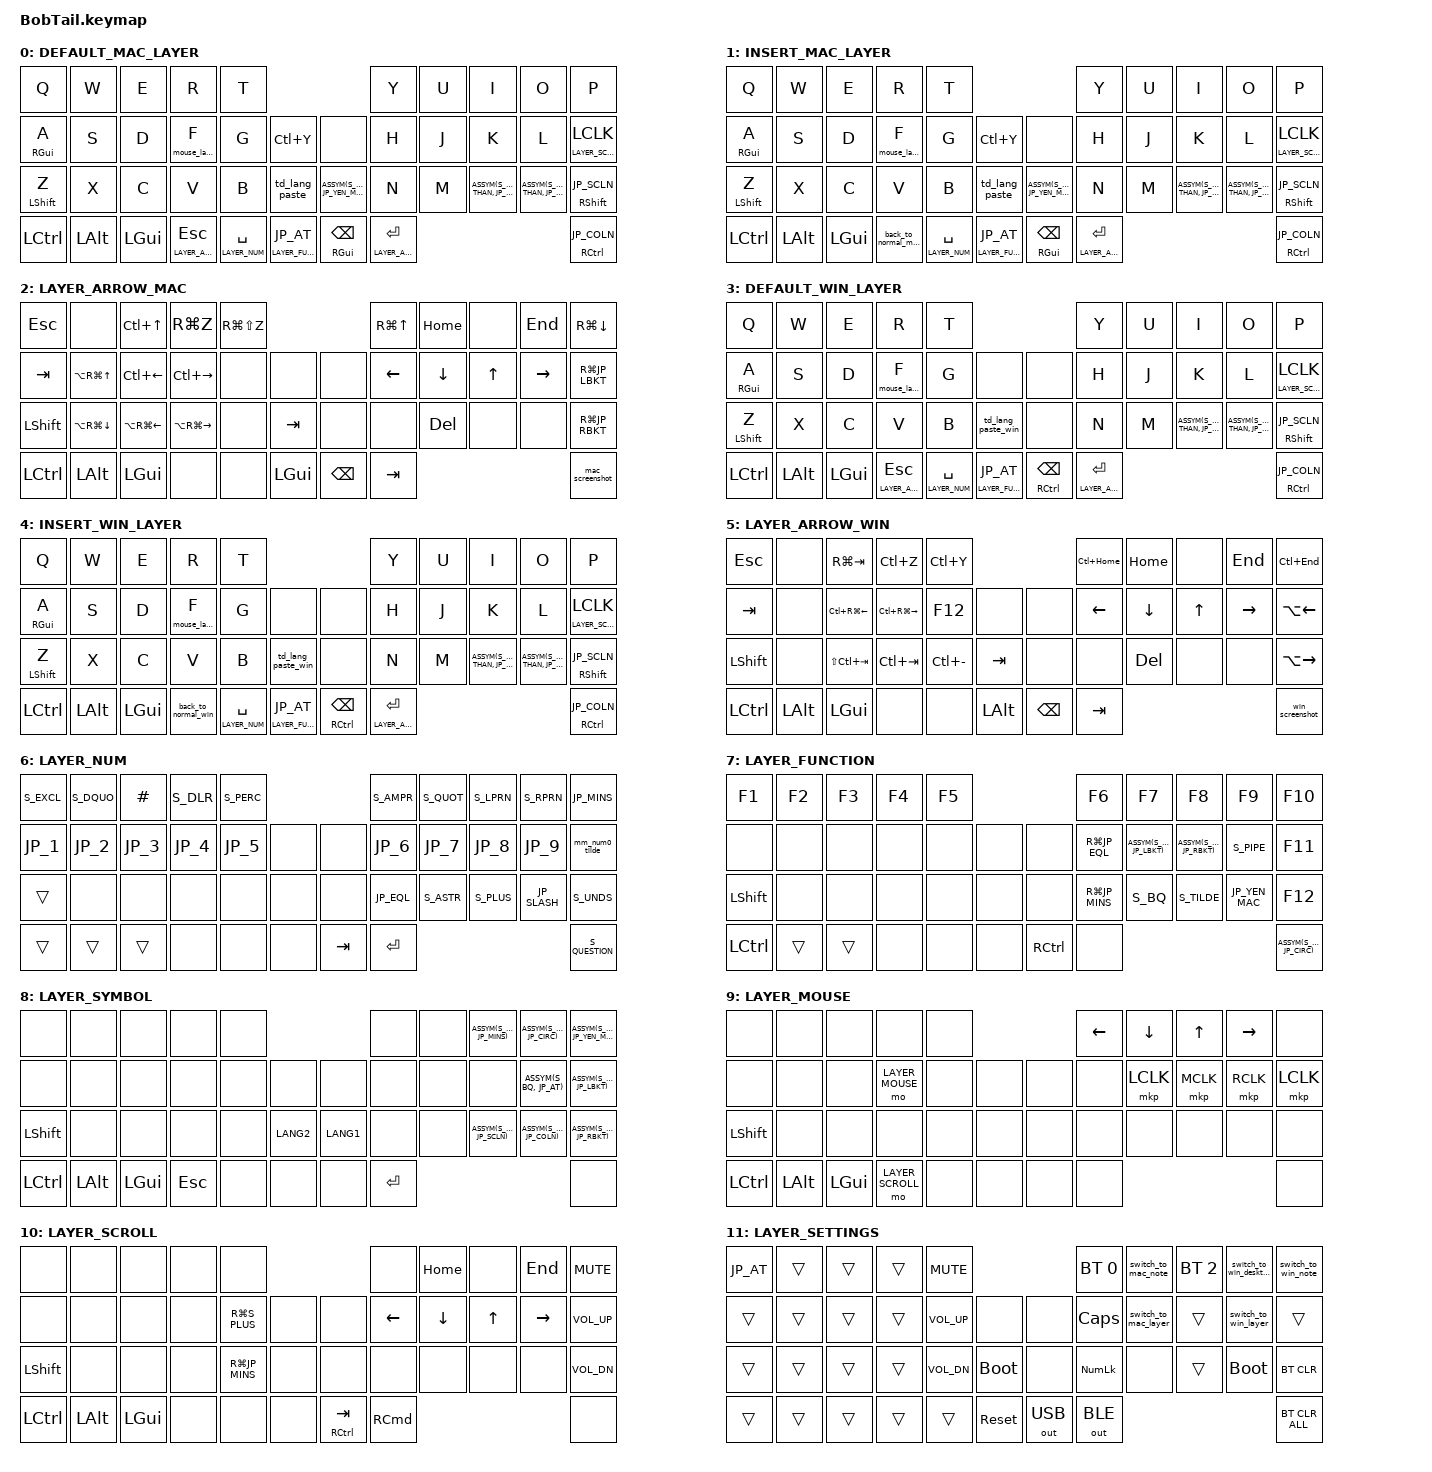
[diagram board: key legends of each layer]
#include <behaviors.dtsi>
#include <dt-bindings/zmk/bt.h>
#include <dt-bindings/zmk/keys.h>
#include <dt-bindings/zmk/outputs.h>
#define ZMK_POINTING_DEFAULT_SCRL_VAL 80
#include <dt-bindings/zmk/pointing.h>
#include <input/processors.dtsi>

#define ASSYM(shifted, keycode) &auto_shift shifted keycode
#include "code.h"

//レイヤー情報
#define DEFAULT_MAC_LAYER 0
#define INSERT_MAC_LAYER 1
#define LAYER_ARROW_MAC 2
#define DEFAULT_WIN_LAYER 3
#define INSERT_WIN_LAYER 4
#define LAYER_ARROW_WIN 5
#define LAYER_NUM 6
#define LAYER_FUNCTION 7
#define LAYER_SYMBOL 8
#define LAYER_MOUSE 9
#define LAYER_SCROLL 10
#define LAYER_SETTINGS 11


&mt {
    flavor = "balanced";
    quick-tap-ms = <0>;
};

/ {
    combos {
        compatible = "zmk,combos";
        to_layer_symbol {
            timeout-ms = <50>;
            bindings = <&toggle_symbol>;
            key-positions = <11 12>;
            layers = <DEFAULT_MAC_LAYER DEFAULT_WIN_LAYER LAYER_SYMBOL>;
        };
        to_layer_settings {
            bindings = <&mo LAYER_SETTINGS>;
            key-positions = <37 38>;
        };
        back_to_default_mac_combo {
            timeout-ms = <800>;
            key-positions = <37 41>;
            bindings = <&back_to_default_mac>;
            layers = <INSERT_MAC_LAYER DEFAULT_MAC_LAYER>;
        };
        back_to_default_win_combo {
            timeout-ms = <800>;
            key-positions = <37 41>;
            bindings = <&back_to_default_win>;
            layers = <INSERT_WIN_LAYER DEFAULT_WIN_LAYER>;
        };
        combo_pipe {
            timeout-ms = <300>;
            key-positions = <13 9>;
            bindings = <&macro_pipe>;
        };
        combo_yen {
            timeout-ms = <300>;
            key-positions = <13 21>;
            bindings = <&macro_yen>;
        };
        combo_under {
            timeout-ms = <300>;
            key-positions = <13 33>;
            bindings = <&macro_under>;
        };
        combo_middle_click {
            timeout-ms = <40>;
            key-positions = <19 20>;
            bindings = <&mkp MCLK>;
            slow-release;
        };
        combo_right_click {
            timeout-ms = <40>;
            key-positions = <20 21>;
            bindings = <&mkp RCLK>;
            slow-release;
        };
    };

    macros {
        mouse_layer_eisu_hold: mouse_layer_eisu_hold {
            compatible = "zmk,behavior-macro";
            #binding-cells = <0>;
            wait-ms = <0>;
            tap-ms = <40>;
            bindings = <&macro_press &mo LAYER_MOUSE>, <&macro_pause_for_release>, <&macro_release &mo LAYER_MOUSE>;
        };
        mouse_button_eisu: mouse_button_eisu {
            compatible = "zmk,behavior-macro-one-param";
            #binding-cells = <1>;
            wait-ms = <30>;
            tap-ms = <40>;
            bindings = <&macro_param_1to1>, <&macro_tap &mkp MACRO_PLACEHOLDER>;
        };
        macro_pipe: macro_pipe {
            compatible = "zmk,behavior-macro";
            #binding-cells = <0>;
            bindings = <&macro_press &kp LALT>, <&macro_tap &kp KP_N1 &kp KP_N2 &kp KP_N4>, <&macro_release &kp LALT>;
        };
        macro_yen: macro_yen {
            compatible = "zmk,behavior-macro";
            #binding-cells = <0>;
            bindings = <&macro_press &kp LALT>, <&macro_tap &kp KP_N1 &kp KP_N6 &kp KP_N5>, <&macro_release &kp LALT>;
        };
        macro_under: macro_under {
            compatible = "zmk,behavior-macro";
            #binding-cells = <0>;
            bindings = <&macro_press &kp LALT>, <&macro_tap &kp KP_N9 &kp KP_N5>, <&macro_release &kp LALT>;
        };
        switch_to_mac_note: switch_to_mac_note {
            compatible = "zmk,behavior-macro";
            #binding-cells = <0>;
            bindings = <&macro_wait_time 50 &bt BT_SEL 1 &bt BT_DISC 0 &bt BT_DISC 2 &bt BT_DISC 3 &bt BT_DISC 4 &out OUT_BLE>;
        };
        switch_to_win_desktop: switch_to_win_desktop {
            compatible = "zmk,behavior-macro";
            #binding-cells = <0>;
            bindings = <&macro_wait_time 50 &bt BT_SEL 3 &bt BT_DISC 0 &bt BT_DISC 1 &bt BT_DISC 2 &bt BT_DISC 4 &out OUT_BLE>;
        };
        switch_to_win_note: switch_to_win_note {
            compatible = "zmk,behavior-macro";
            #binding-cells = <0>;
            bindings = <&macro_wait_time 50 &bt BT_SEL 4 &bt BT_DISC 0 &bt BT_DISC 1 &bt BT_DISC 2 &bt BT_DISC 3 &out OUT_BLE>;
        };
        reset_default_layer: reset_default_layer {
            compatible = "zmk,behavior-macro";
            #binding-cells = <0>;
            bindings = <&toggle_off DEFAULT_MAC_LAYER &toggle_off DEFAULT_WIN_LAYER>;
        };
        switch_to_mac_layer: switch_to_mac_layer {
            compatible = "zmk,behavior-macro";
            #binding-cells = <0>;
            bindings = <&reset_default_layer &macro_wait_time 200 &bt BT_DISC 3 &bt BT_DISC 4 &toggle_on DEFAULT_MAC_LAYER &to DEFAULT_MAC_LAYER &out OUT_BLE>;
        };
        switch_to_win_layer: switch_to_win_layer {
            compatible = "zmk,behavior-macro";
            #binding-cells = <0>;
            bindings = <&reset_default_layer &macro_wait_time 200 &bt BT_DISC 0 &bt BT_DISC 1 &bt BT_DISC 2 &toggle_on DEFAULT_WIN_LAYER &to DEFAULT_WIN_LAYER &out OUT_BLE>;
        };
        mac_screenshot: mac_screenshot {
            compatible = "zmk,behavior-macro";
            #binding-cells = <0>;
            bindings = <&kp RG(LS(N5))>;
        };
        win_screenshot: win_screenshot {
            compatible = "zmk,behavior-macro";
            #binding-cells = <0>;
            bindings = <&kp RG(LS(S))>;
        };
        toggle_symbol: toggle_symbol {
            compatible = "zmk,behavior-macro";
            #binding-cells = <0>;
            bindings = <&tog LAYER_SYMBOL>;
        };
        back_to_normal_mac: back_to_normal_mac {
            compatible = "zmk,behavior-macro";
            #binding-cells = <0>;
            bindings = <&kp ESCAPE &macro_wait_time 50 &to DEFAULT_MAC_LAYER>;
        };
        back_to_normal_win: back_to_normal_win {
            compatible = "zmk,behavior-macro";
            #binding-cells = <0>;
            bindings = <&kp ESCAPE &macro_wait_time 50 &to DEFAULT_WIN_LAYER>;
        };
        back_to_default_mac: back_to_default_mac {
            compatible = "zmk,behavior-macro";
            #binding-cells = <0>;
            bindings = <&to DEFAULT_MAC_LAYER>;
        };
        back_to_default_win: back_to_default_win {
            compatible = "zmk,behavior-macro";
            #binding-cells = <0>;
            bindings = <&to DEFAULT_WIN_LAYER>;
        };
        win_clip_altalt: win_clip_altalt {
            compatible = "zmk,behavior-macro";
            #binding-cells = <0>;
            bindings = <&kp LALT &macro_wait_time 80 &kp LALT>;
        };
        enter_insert_jp_mac: enter_insert_jp_mac {
            compatible = "zmk,behavior-macro";
            #binding-cells = <0>;
            bindings = <&kp LANG1 &macro_wait_time 100 &to INSERT_MAC_LAYER>;
        };
        enter_insert_jp_win: enter_insert_jp_win {
            compatible = "zmk,behavior-macro";
            #binding-cells = <0>;
            bindings = <&kp LANG1 &macro_wait_time 100 &to INSERT_WIN_LAYER>;
        };
    };

    behaviors {
        auto_shift: auto_shift {
            compatible = "zmk,behavior-hold-tap";
            #binding-cells = <2>;
            tapping-term-ms = <180>;
            quick-tap-ms = <200>;
            flavor = "tap-preferred";
            require-prior-idle-ms = <120>;
            bindings = <&kp>, <&kp>;
        };
        lt_arrow: lt_arrow {
            compatible = "zmk,behavior-hold-tap";
            #binding-cells = <2>;
            tapping-term-ms = <250>;
            quick-tap-ms = <200>;
            flavor = "hold-preferred";
            bindings = <&mo>, <&kp>;
        };
        lt_layer_tap_preferred: lt_layer_tap_preferred {
            compatible = "zmk,behavior-hold-tap";
            #binding-cells = <2>;
            tapping-term-ms = <200>;
            flavor = "tap-preferred";
            bindings = <&mo>, <&kp>;
        };
        lt_mkp: lt_mkp {
            compatible = "zmk,behavior-hold-tap";
            #binding-cells = <2>;
            tapping-term-ms = <200>;
            quick-tap-ms = <0>;
            flavor = "hold-preferred";
            bindings = <&mo>, <&mouse_button_eisu>;
        };
        lt_mouse_eisu: lt_mouse_eisu {
            compatible = "zmk,behavior-hold-tap";
            #binding-cells = <2>;
            tapping-term-ms = <200>;
            flavor = "tap-preferred";
            bindings = <&mouse_layer_eisu_hold>, <&kp>;
        };
        lt_layer_tap_preferred_td: lt_layer_tap_preferred_td {
            compatible = "zmk,behavior-hold-tap";
            #binding-cells = <2>;
            tapping-term-ms = <200>;
            flavor = "tap-preferred";
            bindings = <&mo>, <&kp>;
        };
        toggle_on: toggle_layer_on_only {
            compatible = "zmk,behavior-toggle-layer";
            #binding-cells = <1>;
            toggle-mode = "on";
        };
        toggle_off: toggle_layer_off_only {
            compatible = "zmk,behavior-toggle-layer";
            #binding-cells = <1>;
            toggle-mode = "off";
        };
        td_lang_paste: td_lang_paste {
            compatible = "zmk,behavior-tap-dance";
            #binding-cells = <0>;
            tapping-term-ms = <350>;
            bindings = <&kp LANG2>, <&kp LANG1>, <&kp LC(LA(V))>;
        };
        td_lang_paste_win: td_lang_paste_win {
            compatible = "zmk,behavior-tap-dance";
            #binding-cells = <0>;
            tapping-term-ms = <350>;
            bindings = <&kp LANG2>, <&kp LANG1>, <&win_clip_altalt>;
        };
        td_i_insert_mac: td_i_insert_mac {
            compatible = "zmk,behavior-tap-dance";
            #binding-cells = <0>;
            tapping-term-ms = <230>;
            bindings = <&kp I>, <&kp LANG1>;
        };
        td_i_insert_win: td_i_insert_win {
            compatible = "zmk,behavior-tap-dance";
            #binding-cells = <0>;
            tapping-term-ms = <230>;
            bindings = <&kp I>, <&kp LANG1>;
        };
        td_lang1_at: td_lang1_at {
            compatible = "zmk,behavior-tap-dance";
            #binding-cells = <0>;
            tapping-term-ms = <350>;
            bindings = <&kp LANG1>, <&kp JP_AT>;
        };
        mm_num0_tilde: mm_num0_tilde {
            compatible = "zmk,behavior-mod-morph";
            #binding-cells = <0>;
            mods = <(MOD_LSFT | MOD_RSFT)>;
            bindings = <&kp JP_0 &kp JP_CIRC>;
        };
        encoder_msc_down_up: encoder_msc_down_up {
            compatible = "zmk,behavior-sensor-rotate";
            label = "ENCODER_MSC_DOWN_UP";
            #sensor-binding-cells = <0>;
            bindings = <&msc SCRL_UP>,<&msc SCRL_DOWN>;
            tap-ms = <20>;
        };
    };

    keymap {
        compatible = "zmk,keymap";
        DEFAULT_MAC_LAYER {
            bindings = <
                &kp Q                &kp W                &kp E                &kp R                               &kp T                                                                                                                        &kp Y                           &kp U  &kp I                         &kp O                          &kp P
                &mt RIGHT_GUI A      &kp S                &kp D                &lt_mouse_eisu 0 F                  &kp G                                     &kp LC(Y)                                               &none                      &kp H                           &kp J  &kp K                         &kp L                          &lt_mkp LAYER_SCROLL LCLK
                &mt LEFT_SHIFT Z     &kp X                &kp C                &kp V                               &kp B                                     &td_lang_paste                                          ASSYM(S_PIPE, JP_YEN_MAC)  &kp N                           &kp M  ASSYM(S_LESS_THAN, JP_COMMA)  ASSYM(S_GREATER_THAN, JP_DOT)  &mt RIGHT_SHIFT JP_SCLN
                &kp LCTRL            &kp LEFT_ALT         &kp LEFT_GUI         &lt_arrow LAYER_ARROW_MAC ESCAPE    &lt_layer_tap_preferred LAYER_NUM SPACE   &lt_layer_tap_preferred LAYER_FUNCTION JP_AT            &mt RIGHT_GUI BACKSPACE    &lt_arrow LAYER_ARROW_MAC ENTER                                                                     &mt RCTRL JP_COLN
        >;
            sensor-bindings = <&encoder_msc_down_up>;
        };
        INSERT_MAC_LAYER {
            bindings = <
                &kp Q                &kp W                &kp E                &kp R                               &kp T                                                                                                                        &kp Y                           &kp U  &kp I                         &kp O                          &kp P
                &mt RIGHT_GUI A      &kp S                &kp D                &lt_mouse_eisu 0 F                  &kp G                                     &kp LC(Y)                                               &none                      &kp H                           &kp J  &kp K                         &kp L                          &lt_mkp LAYER_SCROLL LCLK
                &mt LEFT_SHIFT Z     &kp X                &kp C                &kp V                               &kp B                                     &td_lang_paste                                          ASSYM(S_PIPE, JP_YEN_MAC)  &kp N                           &kp M  ASSYM(S_LESS_THAN, JP_COMMA)  ASSYM(S_GREATER_THAN, JP_DOT)  &mt RIGHT_SHIFT JP_SCLN
                &kp LCTRL            &kp LEFT_ALT         &kp LEFT_GUI         &back_to_normal_mac                 &lt_layer_tap_preferred LAYER_NUM SPACE   &lt_layer_tap_preferred_td LAYER_FUNCTION JP_AT  &mt RIGHT_GUI BACKSPACE    &lt_arrow LAYER_ARROW_MAC ENTER                                                                     &mt RCTRL JP_COLN
        >;
            sensor-bindings = <&encoder_msc_down_up>;
        };
        LAYER_ARROW_MAC {
            bindings = <
                &kp ESCAPE           &none                   &kp LC(UP_ARROW)        &kp RG(Z)                     &kp RG(LS(Z))                                                                                                    &kp RG(UP_ARROW)     &kp HOME             &none          &kp END              &kp RG(DOWN_ARROW)
                &kp TAB              &kp LA(RG(UP_ARROW))    &kp LC(LEFT_ARROW)      &kp LC(RIGHT_ARROW)           &none                                     &none                                                   &none          &kp LEFT             &kp DOWN_ARROW       &kp UP_ARROW   &kp RIGHT_ARROW      &kp RG(JP_LBKT)
                &kp LEFT_SHIFT       &kp LA(RG(DOWN_ARROW))  &kp LA(RG(LEFT_ARROW))  &kp LA(RG(RIGHT_ARROW))       &none                                     &kp TAB                                                 &none          &none                &kp DELETE           &none          &none                &kp RG(JP_RBKT)
                &kp LCTRL            &kp LEFT_ALT            &kp LEFT_GUI            &none                         &none                                     &kp LEFT_GUI                                            &kp BACKSPACE  &kp TAB                                                                       &mac_screenshot
        >;
                sensor-bindings = <&inc_dec_kp LG(TAB) LS(LG(TAB))>;
        };
        DEFAULT_WIN_LAYER {
            bindings = <
                &kp Q                &kp W                &kp E                &kp R                             &kp T                                                                                                               &kp Y                            &kp U   &kp I                         &kp O                           &kp P
                &mt RIGHT_GUI A      &kp S                &kp D                &lt_mouse_eisu 0 F                &kp G                                    &none                                                 &none                &kp H                            &kp J   &kp K                         &kp L                           &lt_mkp LAYER_SCROLL LCLK
                &mt LEFT_SHIFT Z     &kp X                &kp C                &kp V                             &kp B                                    &td_lang_paste_win                                    &none                &kp N                            &kp M   ASSYM(S_LESS_THAN, JP_COMMA)  ASSYM(S_GREATER_THAN, JP_DOT)   &mt RIGHT_SHIFT JP_SCLN
                &kp LCTRL            &kp LEFT_ALT         &kp LEFT_GUI         &lt_arrow LAYER_ARROW_WIN ESCAPE  &lt_layer_tap_preferred LAYER_NUM SPACE  &lt_layer_tap_preferred LAYER_FUNCTION JP_AT          &mt RCTRL BACKSPACE  &lt_arrow LAYER_ARROW_WIN ENTER                                                                        &mt RCTRL JP_COLN
        >;
            sensor-bindings = <&encoder_msc_down_up>;
        };
        INSERT_WIN_LAYER {
            bindings = <
                &kp Q                &kp W                &kp E                &kp R                &kp T                                                                                                                  &kp Y                            &kp U             &kp I                         &kp O                          &kp P
                &mt RIGHT_GUI A       &kp S                &kp D                &lt_mouse_eisu 0 F   &kp G                                    &none                                                    &none                &kp H                            &kp J             &kp K                         &kp L                          &lt_mkp LAYER_SCROLL LCLK
                &mt LEFT_SHIFT Z     &kp X                &kp C                &kp V                &kp B                                    &td_lang_paste_win                                       &none                &kp N                            &kp M             ASSYM(S_LESS_THAN, JP_COMMA)  ASSYM(S_GREATER_THAN, JP_DOT)  &mt RIGHT_SHIFT JP_SCLN
                &kp LCTRL            &kp LEFT_ALT         &kp LEFT_GUI         &back_to_normal_win  &lt_layer_tap_preferred LAYER_NUM SPACE  &lt_layer_tap_preferred_td LAYER_FUNCTION JP_AT          &mt RCTRL BACKSPACE  &lt_arrow LAYER_ARROW_WIN ENTER                                                                                 &mt RCTRL JP_COLN
        >;
            sensor-bindings = <&encoder_msc_down_up>;
        };
        LAYER_ARROW_WIN {
            bindings = <
                &kp ESCAPE           &none                &kp RG(TAB)          &kp LC(Z)            &kp LC(Y)                                                   &kp LC(HOME)         &kp HOME             &none                &kp END              &kp LC(END)
                &kp TAB              &none                &kp LC(RG(LEFT))     &kp LC(RG(RIGHT))    &kp F12              &none                 &none            &kp LEFT             &kp DOWN_ARROW       &kp UP_ARROW         &kp RIGHT_ARROW      &kp LA(LEFT)
                &kp LEFT_SHIFT       &none                &kp LS(LC(TAB))      &kp LC(TAB)          &kp LC(MINUS)        &kp TAB               &none            &none                &kp DELETE           &none                &none                &kp LA(RIGHT)
                &kp LCTRL            &kp LEFT_ALT         &kp LEFT_GUI         &none                &none                &kp LEFT_ALT          &kp BACKSPACE    &kp TAB                                                                             &win_screenshot
        >;
          sensor-bindings = <&inc_dec_kp LC(TAB) LS(LC(TAB))>;
        };
        LAYER_NUM {
            bindings = <
                &kp S_EXCL           &kp S_DQUO           &kp HASH             &kp S_DLR            &kp S_PERC                                           &kp S_AMPR           &kp S_QUOT           &kp S_LPRN           &kp S_RPRN           &kp JP_MINS
                &kp JP_1             &kp JP_2             &kp JP_3             &kp JP_4             &kp JP_5             &none                  &none    &kp JP_6             &kp JP_7             &kp JP_8             &kp JP_9             &mm_num0_tilde
                &trans               &none                &none                &none                &none                &none                  &none    &kp JP_EQL           &kp S_ASTR           &kp S_PLUS           &kp JP_SLASH         &kp S_UNDS
                &trans               &trans               &trans               &none                &none                &none                  &kp TAB  &kp ENTER                                                                           &kp S_QUESTION
        >;
        };
        LAYER_FUNCTION {
            bindings = <
                &kp F1               &kp F2               &kp F3               &kp F4               &kp F5                                              &kp F6               &kp F7                  &kp F8                  &kp F9               &kp F10
                &none                &none                &none                &none                &none           &none                &none          &kp RG(JP_EQL)       ASSYM(S_LCBR, JP_LBKT)  ASSYM(S_RCBR, JP_RBKT)  &kp S_PIPE           &kp F11
                &kp LEFT_SHIFT       &none                &none                &none                &none           &none                &none          &kp RG(JP_MINS)      &kp S_BQ                &kp S_TILDE             &kp JP_YEN_MAC       &kp F12
                &kp LEFT_CONTROL     &trans               &trans               &none                &none           &none                &kp RCTRL      &none                                                                                     ASSYM(S_TILDE, JP_CIRC)
        >;
        };
        LAYER_SYMBOL {
            bindings = <
                &none                &none                &none                &none                &none                                              &none                &none  ASSYM(S_EQL, JP_MINS)   ASSYM(S_TILDE, JP_CIRC)  ASSYM(S_PIPE, JP_YEN_MAC)
                &none                &none                &none                &none                &none          &none                &none          &none                &none  &none                   ASSYM(S_BQ, JP_AT)       ASSYM(S_LCBR, JP_LBKT)
                &kp LEFT_SHIFT       &none                &none                &none                &none          &kp LANG2            &kp LANG1      &none                &none  ASSYM(S_PLUS, JP_SCLN)  ASSYM(S_ASTR, JP_COLN)   ASSYM(S_RCBR, JP_RBKT)
                &kp LEFT_CONTROL     &kp LEFT_ALT         &kp LEFT_GUI         &kp ESCAPE           &none          &none                &none          &kp ENTER                                                                    &none
        >;
        };
        LAYER_MOUSE {
            bindings = <
                &none                &none                &none                &none                &none                                                     &kp LEFT    &kp DOWN_ARROW    &kp UP_ARROW   &kp RIGHT_ARROW    &none
                &none                &none                &none                &mo LAYER_MOUSE      &none                &none                 &none          &none       &mkp LCLK         &mkp MCLK      &mkp RCLK          &mkp LCLK
                &kp LEFT_SHIFT       &none                &none                &none                &none                &none                 &none          &none       &none             &none          &none              &none
                &kp LCTRL            &kp LEFT_ALT         &kp LEFT_GUI         &mo LAYER_SCROLL     &none                &none                 &none          &none                                                           &none
        >;
        };
        LAYER_SCROLL {
            bindings = <
                &none                &none                &none                &none                &none                                                      &none               &kp HOME         &none           &kp END           &kp C_MUTE
                &none                &none                &none                &none                &kp RG(S_PLUS)       &none                 &none           &kp LEFT            &kp DOWN_ARROW   &kp UP_ARROW    &kp RIGHT_ARROW   &kp C_VOL_UP
                &kp LEFT_SHIFT       &none                &none                &none                &kp RG(JP_MINS)      &none                 &none           &none               &none            &none           &none             &kp C_VOL_DN
                &kp LCTRL            &kp LEFT_ALT         &kp LEFT_GUI         &none                &none                &none                 &mt RCTRL TAB   &kp RIGHT_COMMAND                                                      &none
        >;
                sensor-bindings = <&inc_dec_kp C_VOL_UP C_VOL_DN>;
        };
        LAYER_SETTINGS {
            bindings = <
                &kp JP_AT            &trans               &trans               &trans               &kp C_MUTE                                                &bt BT_SEL 0         &switch_to_mac_note   &bt BT_SEL 2    &switch_to_win_desktop  &switch_to_win_note
                &trans               &trans               &trans               &trans               &kp C_VOL_UP         &none                 &none          &kp CAPS             &switch_to_mac_layer  &trans          &switch_to_win_layer    &trans
                &trans               &trans               &trans               &trans               &kp C_VOL_DN         &bootloader           &none          &kp KP_NUMLOCK       &none                 &trans          &bootloader             &bt BT_CLR
                &trans               &trans               &trans               &trans               &trans               &sys_reset            &out OUT_USB   &out OUT_BLE                                                                       &bt BT_CLR_ALL
        >;
        };
    };
};
